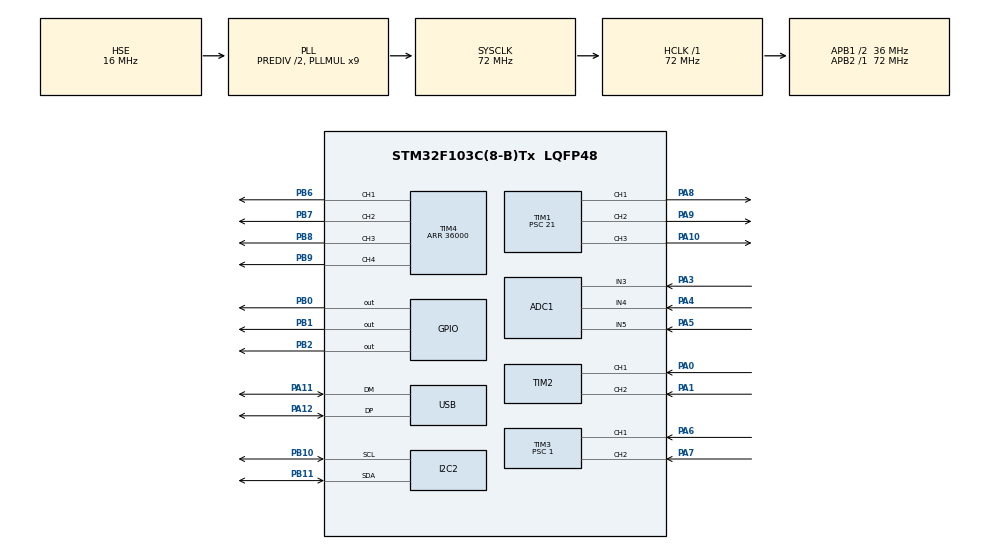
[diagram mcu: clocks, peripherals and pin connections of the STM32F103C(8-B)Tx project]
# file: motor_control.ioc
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ADC1.Channel-20\#ChannelRegularConversion=ADC_CHANNEL_5
ADC1.NbrOfConversionFlag=1
ADC1.Rank-20\#ChannelRegularConversion=1
ADC1.SamplingTime-20\#ChannelRegularConversion=ADC_SAMPLETIME_1CYCLE_5
ADC1.master=1
FREERTOS.Tasks01=defaultTask,24,128,StartDefaultTask,Default,NULL,Dynamic,NULL,NULL
I2C2.DualAddressMode=I2C_DUALADDRESS_DISABLE
I2C2.I2C_Mode=I2C_Standard
I2C2.OwnAddress=0
Mcu.Family=STM32F1
Mcu.Name=STM32F103C(8-B)Tx
Mcu.Package=LQFP48
NVIC.I2C2_ER_IRQn=true\:5\:0\:false\:false\:true\:true\:true\:true\:true
NVIC.I2C2_EV_IRQn=true\:5\:0\:false\:false\:true\:true\:true\:true\:true
NVIC.PriorityGroup=NVIC_PRIORITYGROUP_4
NVIC.USB_LP_CAN1_RX0_IRQn=true\:5\:0\:false\:false\:true\:true\:false\:true\:true
PA0-WKUP.Signal=S_TIM2_CH1_ETR
PA1.Signal=S_TIM2_CH2
PA10.Signal=S_TIM1_CH3
PA11.Mode=Device
PA11.Signal=USB_DM
PA12.Mode=Device
PA12.Signal=USB_DP
PA13.Mode=Serial_Wire
PA13.Signal=SYS_JTMS-SWDIO
PA14.Mode=Serial_Wire
PA14.Signal=SYS_JTCK-SWCLK
PA3.Signal=ADCx_IN3
PA4.Signal=ADCx_IN4
PA5.Signal=ADCx_IN5
PA6.Signal=S_TIM3_CH1
PA7.Signal=S_TIM3_CH2
PA8.Signal=S_TIM1_CH1
PA9.Signal=S_TIM1_CH2
PB0.Signal=GPIO_Output
PB1.Signal=GPIO_Output
PB10.Mode=I2C
PB10.Signal=I2C2_SCL
PB11.Mode=I2C
PB11.Signal=I2C2_SDA
PB2.Signal=GPIO_Output
PB6.Signal=S_TIM4_CH1
PB7.Signal=S_TIM4_CH2
PB8.Signal=S_TIM4_CH3
PB9.Signal=S_TIM4_CH4
PD0-OSC_IN.Mode=HSE-External-Oscillator
PD0-OSC_IN.Signal=RCC_OSC_IN
PD1-OSC_OUT.Mode=HSE-External-Oscillator
PD1-OSC_OUT.Signal=RCC_OSC_OUT
ProjectManager.HeapSize=0x200
ProjectManager.StackSize=0x400
ProjectManager.TargetToolchain=CMake
RCC.ADCPresc=RCC_ADCPCLK2_DIV6
RCC.AHBFreq_Value=72000000
RCC.APB1CLKDivider=RCC_HCLK_DIV2
RCC.APB1Freq_Value=36000000
RCC.APB1TimFreq_Value=72000000
RCC.APB2Freq_Value=72000000
RCC.APB2TimFreq_Value=72000000
RCC.HCLKFreq_Value=72000000
RCC.HSEDivPLL=RCC_HSE_PREDIV_DIV2
RCC.HSE_VALUE=16000000
RCC.PLLMUL=RCC_PLL_MUL9
RCC.SYSCLKFreq_VALUE=72000000
RCC.SYSCLKSource=RCC_SYSCLKSOURCE_PLLCLK
RCC.USBFreq_Value=48000000
RCC.USBPrescaler=RCC_USBCLKSOURCE_PLL_DIV1_5
SH.ADCx_IN3.0=ADC1_IN3,IN3
SH.ADCx_IN4.0=ADC1_IN4,IN4
SH.ADCx_IN5.0=ADC1_IN5,IN5
SH.S_TIM1_CH1.0=TIM1_CH1,PWM Generation1 CH1
SH.S_TIM1_CH2.0=TIM1_CH2,PWM Generation2 CH2
SH.S_TIM1_CH3.0=TIM1_CH3,PWM Generation3 CH3
SH.S_TIM2_CH1_ETR.0=TIM2_CH1,Encoder_Interface
SH.S_TIM2_CH2.0=TIM2_CH2,Encoder_Interface
SH.S_TIM3_CH1.0=TIM3_CH1,Encoder_Interface
SH.S_TIM3_CH2.0=TIM3_CH2,Encoder_Interface
SH.S_TIM4_CH1.0=TIM4_CH1,PWM Generation1 CH1
SH.S_TIM4_CH2.0=TIM4_CH2,PWM Generation2 CH2
SH.S_TIM4_CH3.0=TIM4_CH3,PWM Generation3 CH3
SH.S_TIM4_CH4.0=TIM4_CH4,PWM Generation4 CH4
TIM1.AutoReloadPreload=TIM_AUTORELOAD_PRELOAD_ENABLE
TIM1.Channel-PWM\ Generation1\ CH1=TIM_CHANNEL_1
TIM1.Channel-PWM\ Generation2\ CH2=TIM_CHANNEL_2
TIM1.Channel-PWM\ Generation3\ CH3=TIM_CHANNEL_3
TIM1.Prescaler=21
TIM2.AutoReloadPreload=TIM_AUTORELOAD_PRELOAD_ENABLE
TIM2.EncoderMode=TIM_ENCODERMODE_TI12
TIM2.IC1Filter=10
TIM3.AutoReloadPreload=TIM_AUTORELOAD_PRELOAD_ENABLE
TIM3.EncoderMode=TIM_ENCODERMODE_TI12
TIM3.IC1Filter=10
TIM3.Prescaler=1
TIM4.AutoReloadPreload=TIM_AUTORELOAD_PRELOAD_ENABLE
TIM4.Channel-PWM\ Generation1\ CH1=TIM_CHANNEL_1
TIM4.Channel-PWM\ Generation2\ CH2=TIM_CHANNEL_2
TIM4.Channel-PWM\ Generation3\ CH3=TIM_CHANNEL_3
TIM4.Channel-PWM\ Generation4\ CH4=TIM_CHANNEL_4
TIM4.OCMode_PWM-PWM\ Generation1\ CH1=TIM_OCMODE_PWM2
TIM4.OCMode_PWM-PWM\ Generation2\ CH2=TIM_OCMODE_PWM2
TIM4.OCMode_PWM-PWM\ Generation3\ CH3=TIM_OCMODE_PWM2
TIM4.OCMode_PWM-PWM\ Generation4\ CH4=TIM_OCMODE_PWM2
TIM4.Period=36000
USB_DEVICE.CLASS_NAME_FS=CDC
USB_DEVICE.VirtualMode=Cdc
USB_DEVICE.VirtualModeFS=Cdc_FS
VP_CRC_VS_CRC.Mode=CRC_Activate
VP_FREERTOS_VS_CMSIS_V2.Mode=CMSIS_V2
VP_TIM1_VS_ClockSourceINT.Mode=Internal
VP_TIM4_VS_ClockSourceINT.Mode=Internal
VP_USB_DEVICE_VS_USB_DEVICE_CDC_FS.Mode=CDC_FS
board=custom

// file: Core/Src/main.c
/* USER CODE BEGIN Header */
/**
  ******************************************************************************
  * @file           : main.c
  * @brief          : Main program body
  ******************************************************************************
  * @attention
  *
  * Copyright (c) 2025 STMicroelectronics.
  * All rights reserved.
  *
  * This software is licensed under terms that can be found in the LICENSE file
  * in the root directory of this software component.
  * If no LICENSE file comes with this software, it is provided AS-IS.
  *
  ******************************************************************************
  */
/* USER CODE END Header */
#include "main.h"
#include "cmsis_os.h"
#include "usb_device.h"

/* USER CODE BEGIN Includes */
#include "curverunner.h"
/* USER CODE END Includes */

ADC_HandleTypeDef hadc1;

CRC_HandleTypeDef hcrc;

I2C_HandleTypeDef hi2c2;

TIM_HandleTypeDef htim1;
TIM_HandleTypeDef htim2;
TIM_HandleTypeDef htim3;
TIM_HandleTypeDef htim4;

/* Definitions for defaultTask */
osThreadId_t defaultTaskHandle;
const osThreadAttr_t defaultTask_attributes = {
  .name = "defaultTask",
  .stack_size = 128 * 4,
  .priority = (osPriority_t) osPriorityNormal,
};

void SystemClock_Config(void);
static void MX_GPIO_Init(void);
static void MX_I2C2_Init(void);
static void MX_TIM2_Init(void);
static void MX_TIM3_Init(void);
static void MX_TIM4_Init(void);
static void MX_ADC1_Init(void);
static void MX_TIM1_Init(void);
static void MX_CRC_Init(void);
void StartDefaultTask(void *argument);

int main(void)
{

  /* MCU Configuration--------------------------------------------------------*/

  /* Reset of all peripherals, Initializes the Flash interface and the Systick. */
  HAL_Init();

  /* Configure the system clock */
  SystemClock_Config();

  /* Initialize all configured peripherals */
  MX_GPIO_Init();
  MX_I2C2_Init();
  MX_TIM2_Init();
  MX_TIM3_Init();
  MX_TIM4_Init();
  MX_ADC1_Init();
  MX_TIM1_Init();
  MX_CRC_Init();

  /* Init scheduler */
  osKernelInitialize();

  /* Create the thread(s) */
  /* creation of defaultTask */
  defaultTaskHandle = osThreadNew(StartDefaultTask, NULL, &defaultTask_attributes);

  /* Start scheduler */
  osKernelStart();

  /* We should never get here as control is now taken by the scheduler */

  /* Infinite loop */
  while (1)
  {

  }
}

void SystemClock_Config(void)
{
  RCC_OscInitTypeDef RCC_OscInitStruct = {0};
  RCC_ClkInitTypeDef RCC_ClkInitStruct = {0};
  RCC_PeriphCLKInitTypeDef PeriphClkInit = {0};

  /** Initializes the RCC Oscillators according to the specified parameters
  * in the RCC_OscInitTypeDef structure.
  */
  RCC_OscInitStruct.OscillatorType = RCC_OSCILLATORTYPE_HSE;
  RCC_OscInitStruct.HSEState = RCC_HSE_ON;
  RCC_OscInitStruct.HSEPredivValue = RCC_HSE_PREDIV_DIV2;
  RCC_OscInitStruct.HSIState = RCC_HSI_ON;
  RCC_OscInitStruct.PLL.PLLState = RCC_PLL_ON;
  RCC_OscInitStruct.PLL.PLLSource = RCC_PLLSOURCE_HSE;
  RCC_OscInitStruct.PLL.PLLMUL = RCC_PLL_MUL9;
  if (HAL_RCC_OscConfig(&RCC_OscInitStruct) != HAL_OK)
  {
    Error_Handler();
  }

  /** Initializes the CPU, AHB and APB buses clocks
  */
  RCC_ClkInitStruct.ClockType = RCC_CLOCKTYPE_HCLK|RCC_CLOCKTYPE_SYSCLK
                              |RCC_CLOCKTYPE_PCLK1|RCC_CLOCKTYPE_PCLK2;
  RCC_ClkInitStruct.SYSCLKSource = RCC_SYSCLKSOURCE_PLLCLK;
  RCC_ClkInitStruct.AHBCLKDivider = RCC_SYSCLK_DIV1;
  RCC_ClkInitStruct.APB1CLKDivider = RCC_HCLK_DIV2;
  RCC_ClkInitStruct.APB2CLKDivider = RCC_HCLK_DIV1;

  if (HAL_RCC_ClockConfig(&RCC_ClkInitStruct, FLASH_LATENCY_2) != HAL_OK)
  {
    Error_Handler();
  }
  PeriphClkInit.PeriphClockSelection = RCC_PERIPHCLK_ADC|RCC_PERIPHCLK_USB;
  PeriphClkInit.AdcClockSelection = RCC_ADCPCLK2_DIV6;
  PeriphClkInit.UsbClockSelection = RCC_USBCLKSOURCE_PLL_DIV1_5;
  if (HAL_RCCEx_PeriphCLKConfig(&PeriphClkInit) != HAL_OK)
  {
    Error_Handler();
  }
}

static void MX_ADC1_Init(void)
{

  ADC_ChannelConfTypeDef sConfig = {0};

  /** Common config
  */
  hadc1.Instance = ADC1;
  hadc1.Init.ScanConvMode = ADC_SCAN_DISABLE;
  hadc1.Init.ContinuousConvMode = DISABLE;
  hadc1.Init.DiscontinuousConvMode = DISABLE;
  hadc1.Init.ExternalTrigConv = ADC_SOFTWARE_START;
  hadc1.Init.DataAlign = ADC_DATAALIGN_RIGHT;
  hadc1.Init.NbrOfConversion = 1;
  if (HAL_ADC_Init(&hadc1) != HAL_OK)
  {
    Error_Handler();
  }

  /** Configure Regular Channel
  */
  sConfig.Channel = ADC_CHANNEL_5;
  sConfig.Rank = ADC_REGULAR_RANK_1;
  sConfig.SamplingTime = ADC_SAMPLETIME_1CYCLE_5;
  if (HAL_ADC_ConfigChannel(&hadc1, &sConfig) != HAL_OK)
  {
    Error_Handler();
  }

}

static void MX_CRC_Init(void)
{

  hcrc.Instance = CRC;
  if (HAL_CRC_Init(&hcrc) != HAL_OK)
  {
    Error_Handler();
  }

}

static void MX_I2C2_Init(void)
{

  hi2c2.Instance = I2C2;
  hi2c2.Init.ClockSpeed = 100000;
  hi2c2.Init.DutyCycle = I2C_DUTYCYCLE_2;
  hi2c2.Init.OwnAddress1 = 0;
  hi2c2.Init.AddressingMode = I2C_ADDRESSINGMODE_7BIT;
  hi2c2.Init.DualAddressMode = I2C_DUALADDRESS_DISABLE;
  hi2c2.Init.OwnAddress2 = 0;
  hi2c2.Init.GeneralCallMode = I2C_GENERALCALL_DISABLE;
  hi2c2.Init.NoStretchMode = I2C_NOSTRETCH_DISABLE;
  if (HAL_I2C_Init(&hi2c2) != HAL_OK)
  {
    Error_Handler();
  }

}

static void MX_TIM1_Init(void)
{

  TIM_ClockConfigTypeDef sClockSourceConfig = {0};
  TIM_MasterConfigTypeDef sMasterConfig = {0};
  TIM_OC_InitTypeDef sConfigOC = {0};
  TIM_BreakDeadTimeConfigTypeDef sBreakDeadTimeConfig = {0};

  htim1.Instance = TIM1;
  htim1.Init.Prescaler = 21;
  htim1.Init.CounterMode = TIM_COUNTERMODE_UP;
  htim1.Init.Period = 65535;
  htim1.Init.ClockDivision = TIM_CLOCKDIVISION_DIV1;
  htim1.Init.RepetitionCounter = 0;
  htim1.Init.AutoReloadPreload = TIM_AUTORELOAD_PRELOAD_ENABLE;
  if (HAL_TIM_Base_Init(&htim1) != HAL_OK)
  {
    Error_Handler();
  }
  sClockSourceConfig.ClockSource = TIM_CLOCKSOURCE_INTERNAL;
  if (HAL_TIM_ConfigClockSource(&htim1, &sClockSourceConfig) != HAL_OK)
  {
    Error_Handler();
  }
  if (HAL_TIM_PWM_Init(&htim1) != HAL_OK)
  {
    Error_Handler();
  }
  sMasterConfig.MasterOutputTrigger = TIM_TRGO_RESET;
  sMasterConfig.MasterSlaveMode = TIM_MASTERSLAVEMODE_DISABLE;
  if (HAL_TIMEx_MasterConfigSynchronization(&htim1, &sMasterConfig) != HAL_OK)
  {
    Error_Handler();
  }
  sConfigOC.OCMode = TIM_OCMODE_PWM1;
  sConfigOC.Pulse = 0;
  sConfigOC.OCPolarity = TIM_OCPOLARITY_HIGH;
  sConfigOC.OCNPolarity = TIM_OCNPOLARITY_HIGH;
  sConfigOC.OCFastMode = TIM_OCFAST_DISABLE;
  sConfigOC.OCIdleState = TIM_OCIDLESTATE_RESET;
  sConfigOC.OCNIdleState = TIM_OCNIDLESTATE_RESET;
  if (HAL_TIM_PWM_ConfigChannel(&htim1, &sConfigOC, TIM_CHANNEL_1) != HAL_OK)
  {
    Error_Handler();
  }
  if (HAL_TIM_PWM_ConfigChannel(&htim1, &sConfigOC, TIM_CHANNEL_2) != HAL_OK)
  {
    Error_Handler();
  }
  if (HAL_TIM_PWM_ConfigChannel(&htim1, &sConfigOC, TIM_CHANNEL_3) != HAL_OK)
  {
    Error_Handler();
  }
  sBreakDeadTimeConfig.OffStateRunMode = TIM_OSSR_DISABLE;
  sBreakDeadTimeConfig.OffStateIDLEMode = TIM_OSSI_DISABLE;
  sBreakDeadTimeConfig.LockLevel = TIM_LOCKLEVEL_OFF;
  sBreakDeadTimeConfig.DeadTime = 0;
  sBreakDeadTimeConfig.BreakState = TIM_BREAK_DISABLE;
  sBreakDeadTimeConfig.BreakPolarity = TIM_BREAKPOLARITY_HIGH;
  sBreakDeadTimeConfig.AutomaticOutput = TIM_AUTOMATICOUTPUT_DISABLE;
  if (HAL_TIMEx_ConfigBreakDeadTime(&htim1, &sBreakDeadTimeConfig) != HAL_OK)
  {
    Error_Handler();
  }
  HAL_TIM_MspPostInit(&htim1);

}

static void MX_TIM2_Init(void)
{

  TIM_Encoder_InitTypeDef sConfig = {0};
  TIM_MasterConfigTypeDef sMasterConfig = {0};

  htim2.Instance = TIM2;
  htim2.Init.Prescaler = 0;
  htim2.Init.CounterMode = TIM_COUNTERMODE_UP;
  htim2.Init.Period = 65535;
  htim2.Init.ClockDivision = TIM_CLOCKDIVISION_DIV1;
  htim2.Init.AutoReloadPreload = TIM_AUTORELOAD_PRELOAD_ENABLE;
  sConfig.EncoderMode = TIM_ENCODERMODE_TI12;
  sConfig.IC1Polarity = TIM_ICPOLARITY_RISING;
  sConfig.IC1Selection = TIM_ICSELECTION_DIRECTTI;
  sConfig.IC1Prescaler = TIM_ICPSC_DIV1;
  sConfig.IC1Filter = 10;
  sConfig.IC2Polarity = TIM_ICPOLARITY_RISING;
  sConfig.IC2Selection = TIM_ICSELECTION_DIRECTTI;
  sConfig.IC2Prescaler = TIM_ICPSC_DIV1;
  sConfig.IC2Filter = 0;
  if (HAL_TIM_Encoder_Init(&htim2, &sConfig) != HAL_OK)
  {
    Error_Handler();
  }
  sMasterConfig.MasterOutputTrigger = TIM_TRGO_RESET;
  sMasterConfig.MasterSlaveMode = TIM_MASTERSLAVEMODE_DISABLE;
  if (HAL_TIMEx_MasterConfigSynchronization(&htim2, &sMasterConfig) != HAL_OK)
  {
    Error_Handler();
  }

}

static void MX_TIM3_Init(void)
{

  TIM_Encoder_InitTypeDef sConfig = {0};
  TIM_MasterConfigTypeDef sMasterConfig = {0};

  htim3.Instance = TIM3;
  htim3.Init.Prescaler = 1;
  htim3.Init.CounterMode = TIM_COUNTERMODE_UP;
  htim3.Init.Period = 65535;
  htim3.Init.ClockDivision = TIM_CLOCKDIVISION_DIV1;
  htim3.Init.AutoReloadPreload = TIM_AUTORELOAD_PRELOAD_ENABLE;
  sConfig.EncoderMode = TIM_ENCODERMODE_TI12;
  sConfig.IC1Polarity = TIM_ICPOLARITY_RISING;
  sConfig.IC1Selection = TIM_ICSELECTION_DIRECTTI;
  sConfig.IC1Prescaler = TIM_ICPSC_DIV1;
  sConfig.IC1Filter = 10;
  sConfig.IC2Polarity = TIM_ICPOLARITY_RISING;
  sConfig.IC2Selection = TIM_ICSELECTION_DIRECTTI;
  sConfig.IC2Prescaler = TIM_ICPSC_DIV1;
  sConfig.IC2Filter = 0;
  if (HAL_TIM_Encoder_Init(&htim3, &sConfig) != HAL_OK)
  {
    Error_Handler();
  }
  sMasterConfig.MasterOutputTrigger = TIM_TRGO_RESET;
  sMasterConfig.MasterSlaveMode = TIM_MASTERSLAVEMODE_DISABLE;
  if (HAL_TIMEx_MasterConfigSynchronization(&htim3, &sMasterConfig) != HAL_OK)
  {
    Error_Handler();
  }

}

static void MX_TIM4_Init(void)
{

  TIM_ClockConfigTypeDef sClockSourceConfig = {0};
  TIM_MasterConfigTypeDef sMasterConfig = {0};
  TIM_OC_InitTypeDef sConfigOC = {0};

  htim4.Instance = TIM4;
  htim4.Init.Prescaler = 0;
  htim4.Init.CounterMode = TIM_COUNTERMODE_UP;
  htim4.Init.Period = 36000;
  htim4.Init.ClockDivision = TIM_CLOCKDIVISION_DIV1;
  htim4.Init.AutoReloadPreload = TIM_AUTORELOAD_PRELOAD_ENABLE;
  if (HAL_TIM_Base_Init(&htim4) != HAL_OK)
  {
    Error_Handler();
  }
  sClockSourceConfig.ClockSource = TIM_CLOCKSOURCE_INTERNAL;
  if (HAL_TIM_ConfigClockSource(&htim4, &sClockSourceConfig) != HAL_OK)
  {
    Error_Handler();
  }
  if (HAL_TIM_PWM_Init(&htim4) != HAL_OK)
  {
    Error_Handler();
  }
  sMasterConfig.MasterOutputTrigger = TIM_TRGO_RESET;
  sMasterConfig.MasterSlaveMode = TIM_MASTERSLAVEMODE_DISABLE;
  if (HAL_TIMEx_MasterConfigSynchronization(&htim4, &sMasterConfig) != HAL_OK)
  {
    Error_Handler();
  }
  sConfigOC.OCMode = TIM_OCMODE_PWM2;
  sConfigOC.Pulse = 0;
  sConfigOC.OCPolarity = TIM_OCPOLARITY_HIGH;
  sConfigOC.OCFastMode = TIM_OCFAST_DISABLE;
  if (HAL_TIM_PWM_ConfigChannel(&htim4, &sConfigOC, TIM_CHANNEL_1) != HAL_OK)
  {
    Error_Handler();
  }
  if (HAL_TIM_PWM_ConfigChannel(&htim4, &sConfigOC, TIM_CHANNEL_2) != HAL_OK)
  {
    Error_Handler();
  }
  if (HAL_TIM_PWM_ConfigChannel(&htim4, &sConfigOC, TIM_CHANNEL_3) != HAL_OK)
  {
    Error_Handler();
  }
  if (HAL_TIM_PWM_ConfigChannel(&htim4, &sConfigOC, TIM_CHANNEL_4) != HAL_OK)
  {
    Error_Handler();
  }
  HAL_TIM_MspPostInit(&htim4);

}

static void MX_GPIO_Init(void)
{
  GPIO_InitTypeDef GPIO_InitStruct = {0};

  /* GPIO Ports Clock Enable */
  __HAL_RCC_GPIOD_CLK_ENABLE();
  __HAL_RCC_GPIOA_CLK_ENABLE();
  __HAL_RCC_GPIOB_CLK_ENABLE();

  /*Configure GPIO pin Output Level */
  HAL_GPIO_WritePin(GPIOB, GPIO_PIN_0|GPIO_PIN_1|GPIO_PIN_2, GPIO_PIN_RESET);

  /*Configure GPIO pins : PB0 PB1 PB2 */
  GPIO_InitStruct.Pin = GPIO_PIN_0|GPIO_PIN_1|GPIO_PIN_2;
  GPIO_InitStruct.Mode = GPIO_MODE_OUTPUT_PP;
  GPIO_InitStruct.Pull = GPIO_NOPULL;
  GPIO_InitStruct.Speed = GPIO_SPEED_FREQ_LOW;
  HAL_GPIO_Init(GPIOB, &GPIO_InitStruct);

}

void StartDefaultTask(void *argument)
{
  /* init code for USB_DEVICE */
  MX_USB_DEVICE_Init();
  /* USER CODE BEGIN 5 */
  curverunner_main(argument);
  /* Infinite loop */
  for(;;)
  {
    osDelay(1);
  }
  /* USER CODE END 5 */
}

void Error_Handler(void)
{
  __disable_irq();
  while (1)
  {
  }
}
